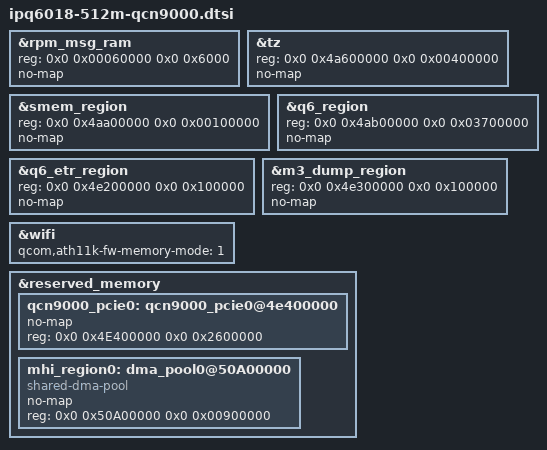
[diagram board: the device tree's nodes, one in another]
// SPDX-License-Identifier: GPL-2.0-only

#include "ipq6018.dtsi"

&rpm_msg_ram {
	reg = <0x0 0x00060000 0x0 0x6000>;
	no-map;
};

&tz {
	reg = <0x0 0x4a600000 0x0 0x00400000>;
	no-map;
};

&smem_region {
	reg = <0x0 0x4aa00000 0x0 0x00100000>;
	no-map;
};

&q6_region {
	reg = <0x0 0x4ab00000 0x0 0x03700000>;
	no-map;
};

&q6_etr_region {
	reg = <0x0 0x4e200000 0x0 0x100000>;
	no-map;
};

&m3_dump_region {
	reg = <0x0 0x4e300000 0x0 0x100000>;
	no-map;
};

&wifi {
	qcom,ath11k-fw-memory-mode = <1>;
};

&reserved_memory {
		qcn9000_pcie0: qcn9000_pcie0@4e400000 {
			no-map;
			reg = <0x0 0x4E400000 0x0 0x2600000>;
		};

		mhi_region0: dma_pool0@50A00000 {
			compatible = "shared-dma-pool";
			no-map;
			reg = <0x0 0x50A00000 0x0 0x00900000>;
		};
};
